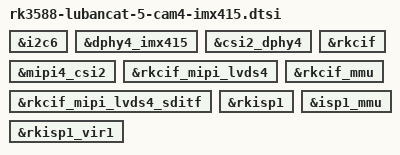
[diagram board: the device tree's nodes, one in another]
&i2c6 {
	status = "okay";
};

&dphy4_imx415 {
	status = "okay";
};

&csi2_dphy4 {
	status = "okay";
};

&mipi4_csi2 {
	status = "okay";
};

&rkcif {
	status = "okay";
};

&rkcif_mipi_lvds4 {
	status = "okay";
};

&rkcif_mipi_lvds4_sditf {
	status = "okay";
};

&rkcif_mmu {
	status = "okay";
};

&rkisp1 {
	status = "okay";
};

&isp1_mmu {
	status = "okay";
};

&rkisp1_vir1 {
	status = "okay";
};

